AUTOSAR XML (schema 4-3-0)
package /ComponentTypes
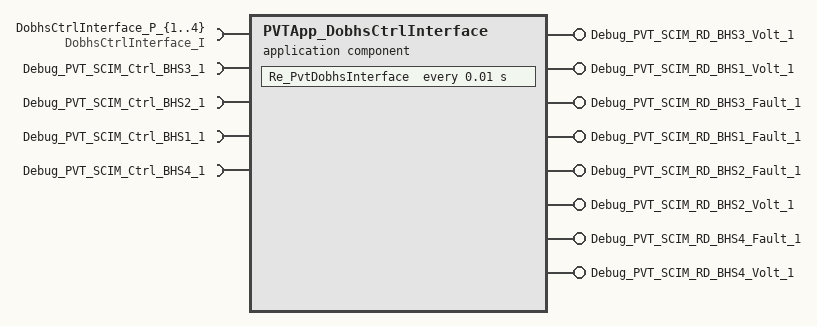
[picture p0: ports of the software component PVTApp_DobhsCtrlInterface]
  application sw component type PVTApp_DobhsCtrlInterface
    8 x require port:
      DobhsCtrlInterface_P_{1..4}: required-com-specs=[SetDobhsActive, GetDobhsPinState], required-interface=DobhsCtrlInterface_I
      Debug_PVT_SCIM_Ctrl_BHS3_1: nonqueued-receiver-com-spec{data-element=Debug_PVT_SCIM_Ctrl_BHS3, init-value=0}, required-interface=Debug_PVT_SCIM_Ctrl_BHS3_1
      Debug_PVT_SCIM_Ctrl_BHS2_1: nonqueued-receiver-com-spec{data-element=Debug_PVT_SCIM_Ctrl_BHS2, init-value=0}, required-interface=Debug_PVT_SCIM_Ctrl_BHS2_1
      Debug_PVT_SCIM_Ctrl_BHS1_1: nonqueued-receiver-com-spec{data-element=Debug_PVT_SCIM_Ctrl_BHS1, init-value=0}, required-interface=Debug_PVT_SCIM_Ctrl_BHS1_1
      Debug_PVT_SCIM_Ctrl_BHS4_1: nonqueued-receiver-com-spec{data-element=Debug_PVT_SCIM_Ctrl_BHS4, init-value=0}, required-interface=Debug_PVT_SCIM_Ctrl_BHS4_1
    8 x provide port:
      Debug_PVT_SCIM_RD_BHS3_Volt_1: nonqueued-sender-com-spec{data-element=Debug_PVT_SCIM_RD_BHS3_Volt, init-value=0}, provided-interface=Debug_PVT_SCIM_RD_BHS3_Volt_1
      Debug_PVT_SCIM_RD_BHS1_Volt_1: nonqueued-sender-com-spec{data-element=Debug_PVT_SCIM_RD_BHS1_Volt, init-value=0}, provided-interface=Debug_PVT_SCIM_RD_BHS1_Volt_1
      Debug_PVT_SCIM_RD_BHS3_Fault_1: nonqueued-sender-com-spec{data-element=Debug_PVT_SCIM_RD_BHS3_Fault, init-value=0}, provided-interface=Debug_PVT_SCIM_RD_BHS3_Fault_1
      Debug_PVT_SCIM_RD_BHS1_Fault_1: nonqueued-sender-com-spec{data-element=Debug_PVT_SCIM_RD_BHS1_Fault, init-value=0}, provided-interface=Debug_PVT_SCIM_RD_BHS1_Fault_1
      Debug_PVT_SCIM_RD_BHS2_Fault_1: nonqueued-sender-com-spec{data-element=Debug_PVT_SCIM_RD_BHS2_Fault, init-value=0}, provided-interface=Debug_PVT_SCIM_RD_BHS2_Fault_1
      Debug_PVT_SCIM_RD_BHS2_Volt_1: nonqueued-sender-com-spec{data-element=Debug_PVT_SCIM_RD_BHS2_Volt, init-value=0}, provided-interface=Debug_PVT_SCIM_RD_BHS2_Volt_1
      Debug_PVT_SCIM_RD_BHS4_Fault_1: nonqueued-sender-com-spec{data-element=Debug_PVT_SCIM_RD_BHS4_Fault, init-value=0}, provided-interface=Debug_PVT_SCIM_RD_BHS4_Fault_1
      Debug_PVT_SCIM_RD_BHS4_Volt_1: nonqueued-sender-com-spec{data-element=Debug_PVT_SCIM_RD_BHS4_Volt, init-value=0}, provided-interface=Debug_PVT_SCIM_RD_BHS4_Volt_1
    behavior PVTApp_DobhsCtrlInterface_InternalBehavior
      timing event TMT_Re_PvtDobhsInterface: start-on-event=Re_PvtDobhsInterface, period=0.01
      runnable Re_PvtDobhsInterface
        data-receive-point-by-values:
          4 x access:
            REC_Debug_PVT_SCIM_Ctrl_BHS{1..4}_1_Debug_PVT_SCIM_Ctrl_BHS{1..4}: accessed-variable=Debug_PVT_SCIM_Ctrl_BHS{1..4}_1.Debug_PVT_SCIM_Ctrl_BHS{1..4}
        data-send-points:
          8 x access:
            SEND_Debug_PVT_SCIM_RD_BHS1_Fault_1_Debug_PVT_SCIM_RD_BHS1_Fault: accessed-variable=Debug_PVT_SCIM_RD_BHS1_Fault_1.Debug_PVT_SCIM_RD_BHS1_Fault
            SEND_Debug_PVT_SCIM_RD_BHS1_Volt_1_Debug_PVT_SCIM_RD_BHS1_Volt: accessed-variable=Debug_PVT_SCIM_RD_BHS1_Volt_1.Debug_PVT_SCIM_RD_BHS1_Volt
            SEND_Debug_PVT_SCIM_RD_BHS2_Fault_1_Debug_PVT_SCIM_RD_BHS2_Fault: accessed-variable=Debug_PVT_SCIM_RD_BHS2_Fault_1.Debug_PVT_SCIM_RD_BHS2_Fault
            SEND_Debug_PVT_SCIM_RD_BHS2_Volt_1_Debug_PVT_SCIM_RD_BHS2_Volt: accessed-variable=Debug_PVT_SCIM_RD_BHS2_Volt_1.Debug_PVT_SCIM_RD_BHS2_Volt
            SEND_Debug_PVT_SCIM_RD_BHS3_Fault_1_Debug_PVT_SCIM_RD_BHS3_Fault: accessed-variable=Debug_PVT_SCIM_RD_BHS3_Fault_1.Debug_PVT_SCIM_RD_BHS3_Fault
            SEND_Debug_PVT_SCIM_RD_BHS3_Volt_1_Debug_PVT_SCIM_RD_BHS3_Volt: accessed-variable=Debug_PVT_SCIM_RD_BHS3_Volt_1.Debug_PVT_SCIM_RD_BHS3_Volt
            SEND_Debug_PVT_SCIM_RD_BHS4_Fault_1_Debug_PVT_SCIM_RD_BHS4_Fault: accessed-variable=Debug_PVT_SCIM_RD_BHS4_Fault_1.Debug_PVT_SCIM_RD_BHS4_Fault
            SEND_Debug_PVT_SCIM_RD_BHS4_Volt_1_Debug_PVT_SCIM_RD_BHS4_Volt: accessed-variable=Debug_PVT_SCIM_RD_BHS4_Volt_1.Debug_PVT_SCIM_RD_BHS4_Volt
        8 x sync call:
          SC_DobhsCtrlInterface_P_1_GetDobhsPinState: operation=DobhsCtrlInterface_P_1.GetDobhsPinState
          SC_DobhsCtrlInterface_P_1_SetDobhsActive: operation=DobhsCtrlInterface_P_1.SetDobhsActive
          SC_DobhsCtrlInterface_P_2_GetDobhsPinState: operation=DobhsCtrlInterface_P_2.GetDobhsPinState
          SC_DobhsCtrlInterface_P_2_SetDobhsActive: operation=DobhsCtrlInterface_P_2.SetDobhsActive
          SC_DobhsCtrlInterface_P_3_GetDobhsPinState: operation=DobhsCtrlInterface_P_3.GetDobhsPinState
          SC_DobhsCtrlInterface_P_3_SetDobhsActive: operation=DobhsCtrlInterface_P_3.SetDobhsActive
          SC_DobhsCtrlInterface_P_4_GetDobhsPinState: operation=DobhsCtrlInterface_P_4.GetDobhsPinState
          SC_DobhsCtrlInterface_P_4_SetDobhsActive: operation=DobhsCtrlInterface_P_4.SetDobhsActive
  swc implementation PVTApp_DobhsCtrlInterface_Implementation: behavior=PVTApp_DobhsCtrlInterface_InternalBehavior
    code-descriptors:
      code Default: artifact-descriptors=autosar-engineering-object=category=SWSRC
